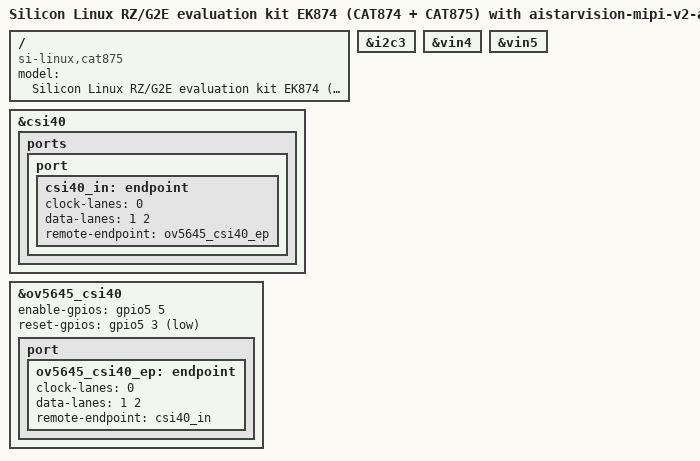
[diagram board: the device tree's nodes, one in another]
// SPDX-License-Identifier: GPL-2.0
/*
 * Device Tree Source for the Silicon Linux RZ/G2E 96board platform (CAT874)
 * Rev.C connected with aistarvision-mipi-v2-adapter board
 *
 * Copyright (C) 2020 Renesas Electronics Corp.
 */

/dts-v1/;
#include "r8a774c0-ek874-revc.dts"
#define MIPI_OV5645_PARENT_I2C_CSI40 i2c3
#include "aistarvision-mipi-adapter-2.4.dtsi"

/ {
	model = "Silicon Linux RZ/G2E evaluation kit EK874 (CAT874 + CAT875) with aistarvision-mipi-v2-adapter board";
	compatible = "si-linux,cat875", "si-linux,cat874", "renesas,r8a774c0";
};

&i2c3 {
	status = "okay";
};

&vin4 {
	status = "okay";
};

&vin5 {
	status = "okay";
};

&csi40 {
	status = "okay";

	ports {
		port {
			csi40_in: endpoint {
				clock-lanes = <0>;
				data-lanes = <1 2>;
				remote-endpoint = <&ov5645_csi40_ep>;
			};
		};
	};
};

&ov5645_csi40 {
	enable-gpios = <&gpio5 5 GPIO_ACTIVE_HIGH>;
	reset-gpios = <&gpio5 3 GPIO_ACTIVE_LOW>;

	port {
		ov5645_csi40_ep: endpoint {
			clock-lanes = <0>;
			data-lanes = <1 2>;
			remote-endpoint = <&csi40_in>;
		};
	};
};
